# TC37X register map
File version: 1.0.0
CPU: CM4 r0p1, little endian, MPU, FPU, VTOR, 3 interrupt priority bits
Registers are 16-bit, read-write, reset 0x0 unless marked. A register's access mark holds for its fields unless they carry their own. Offsets are from the block's base; [hi:lo] are bit positions; {n}, {i} and the like mark numbered series.

## IOM — ce_iom
Base 0xF0035000
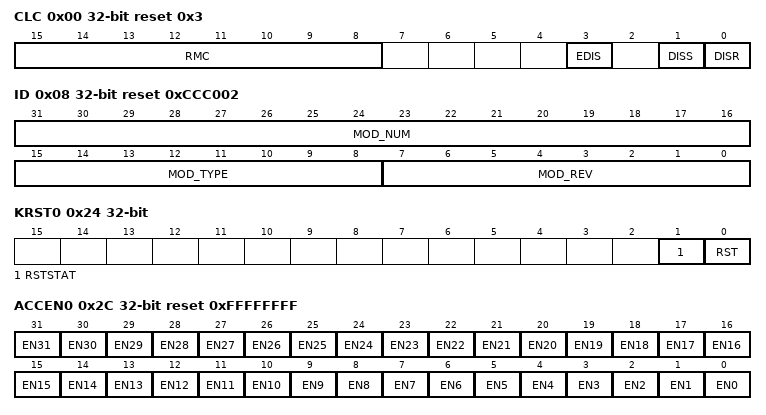
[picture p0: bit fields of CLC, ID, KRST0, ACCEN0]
0x00 CLC 32-bit reset 0x3 — IOM Clock Control Register
  [15:8] RMC — 8-bit Clock Divider Value in RUN Mode - RMC
  [3] EDIS — Sleep Mode Enable Control - EDIS
  [1] DISS ro — Module Disable Status Bit - DISS
  [0] DISR — Module Disable Request Bit - DISR
0x08 ID 32-bit ro reset 0xCCC002 — IOM Identification Register
  [31:16] MOD_NUM — Module Number Value - MOD_NUM
  [15:8] MOD_TYPE — Module Number Value - MOD_TYPE
  [7:0] MOD_REV — Module Revision Number - MOD_REV
0x1C KRSTCLR 32-bit wo — IOM Kernel Reset Status Clear Register
  [0] CLR — Kernel Reset Status Clear - CLR
0x20 KRST1 32-bit — IOM Kernel Reset Register 1
  [0] RST — Kernel Reset - RST
0x24 KRST0 32-bit — IOM Kernel Reset Register 0
  [1] RSTSTAT ro — Kernel Reset Status - RSTSTAT
  [0] RST — Kernel Reset - RST
0x28 ACCEN1 32-bit ro — IOM Access Enable Register 1
0x2C ACCEN0 32-bit reset 0xFFFFFFFF — IOM Access Enable Register 0
  [n] EN{n} (n=0..31) — Access Enable for Master TAG ID {n} - EN{n}
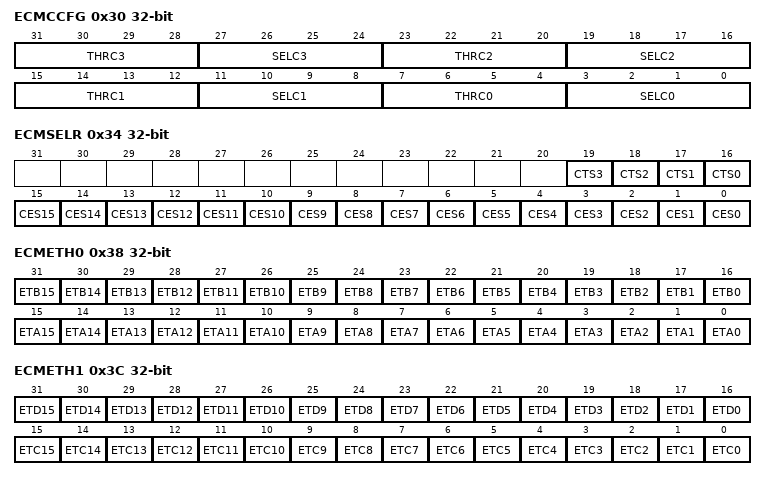
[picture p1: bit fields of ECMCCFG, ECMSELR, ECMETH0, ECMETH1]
0x30 ECMCCFG 32-bit — IOM Event Combiner Module Counter Configuration Register
  [8n+7:8n+4] THRC{n} (n=0..3) — Channel Event Counter Threshold
  [8n+3:8n] SELC{n} (n=0..3) — Event Channel Select
0x34 ECMSELR 32-bit — IOM Event Combiner Module Global Event Selection Register
  [n+16] CTS{n} (n=0..3) — Accumulated (Cou{n}ted) Event Combiner Selection - CTS{n}
  [n] CES{n} (n=0..15) — Eve{n}t Combiner Selection - CES{n}
0x38 ECMETH0 32-bit — IOM Event Combiner Module Event Trigger History Register 0
  [n+16] ETB{n} (n=0..15) — LAM 0-15 Eve{n}t Trigger Activity (previous ETA0-15) - ETB{n}
  [n] ETA{n} (n=0..15) — LAM 0-15 Eve{n}t Trigger Activity (last) - ETA{n}
0x3C ECMETH1 32-bit — IOM Event Combiner Module Event Trigger History Register 1
  [n+16] ETD{n} (n=0..15) — LAM 0-15 Event Trigger Activity (previous contents of ETC0-15 ORed with the previous value of ETD0-15)
  [n] ETC{n} (n=0..15) — LAM 0-15 Eve{n}t Trigger Activity (previous ETB0-15) - ETC{n}
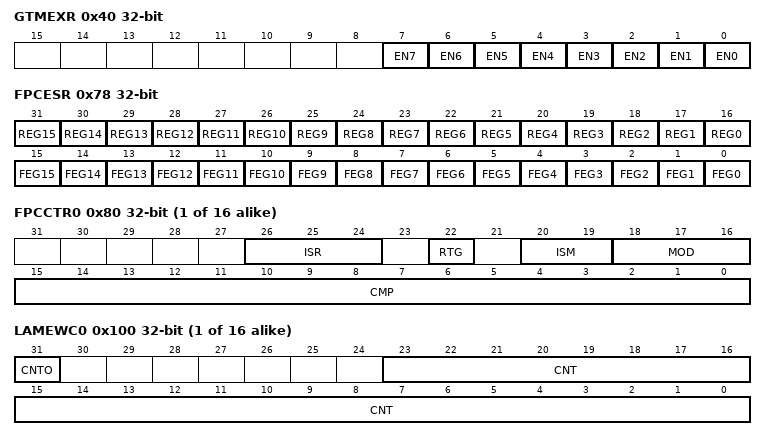
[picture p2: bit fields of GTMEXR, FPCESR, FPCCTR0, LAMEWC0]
0x40 GTMEXR 32-bit — IOM GTM Input EXOR Combiner Selection Register
  [n] EN{n} (n=0..7) — GTM input {n} selection for EXOR combiner - EN{n}
0x78 FPCESR 32-bit — IOM Filter and Prescaler Channels Rising & Falling Edge Status Register
  [n+16] REG{n} (n=0..15) — Rising Edge Glitch Flag for FPC{n} - REG{n}
  [n] FEG{n} (n=0..15) — Falling Edge Glitch Flag for FPC{n} - FEG{n}
{0x80+4i} FPCCTR{i} 32-bit (i=0..15) — IOM Filter and Prescaler Channel Control Register {i}
  [26:24] ISR — Reference Input Signal Selection for Filter & Prescaler Channel k - ISR
  [22] RTG — Reset Timer behavior for Filter & Prescaler Channel k on Glitch - RTG
  [20:19] ISM — Monitor Input Signal Selection for Filter & Prescaler Channel k - ISM
  [18:16] MOD — Operation Mode Selection for Filter & Prescaler Channel k - MOD
  [15:0] CMP — Threshold Value of Filter & Prescaler Channel k - CMP
{0xC0+4i} FPCTIM{i} 32-bit (i=0..15) — IOM Filter and Prescaler Channel Timer Register {i}
  [15:0] TIM — Timer Value of Filter and Prescaler Channel k - TIM
{0x100+4i} LAMEWC{i} 32-bit (i=0..15) — IOM Logic Analyzer Module Event Window Count Status Register {i}
  [31] CNTO — Count Overflow Flag LAM block m - CNTO
  [23:0] CNT — Event Window Count Value LAM block m - CNT
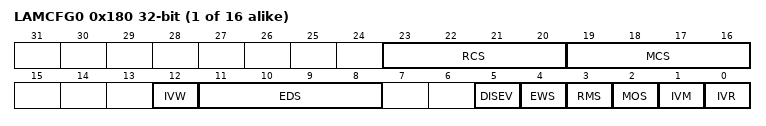
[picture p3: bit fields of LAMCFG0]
{0x180+4i} LAMCFG{i} 32-bit (i=0..15) — IOM Logic Analyzer Module Configuration Register {i}
  [23:20] RCS — Reference Input Signal Selection LAM block m - RCS
  [19:16] MCS — Monitor Input Signal Selection LAM block m - MCS
  [12] IVW — Invert Event Window LAM block m - IVW
  [11:8] EDS — Event Window Active Edge Selection LAM block m - EDS
  [5] DISEV — Disable Events LAM block m - DISEV
  [4] EWS — Event Window Select LAM block m - EWS
  [3] RMS — Runmode Select LAM block m - RMS
  [2] MOS — Monitor Source Select LAM block m - MOS
  [1] IVM — Invert Monitor LAM block m - IVM
  [0] IVR — Invert Reference LAM block m - IVR
{0x1C0+4i} LAMEWS{i} 32-bit (i=0..15) — IOM Logic Analyzer Module Event Window Configuration Register {i}
  [23:0] THR — Event Window Count Threshold - THR
